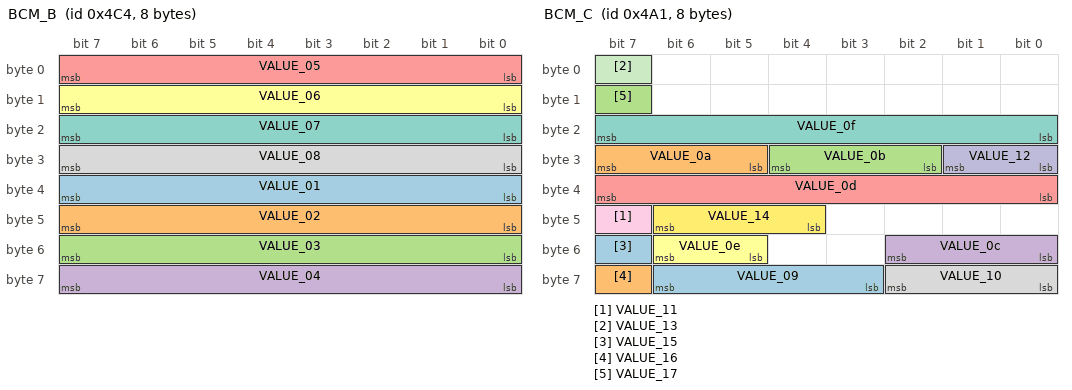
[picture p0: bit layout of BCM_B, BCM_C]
BO_ 1220 BCM_B: 8 BCM
 SG_ VALUE_01 : 39|8@0+ (1,0) [0|0] "" FCDIM
 SG_ VALUE_02 : 47|8@0+ (1,0) [0|0] "" FCDIM
 SG_ VALUE_03 : 55|8@0+ (1,0) [0|0] "" FCDIM
 SG_ VALUE_04 : 63|8@0+ (1,0) [0|0] "" FCDIM
 SG_ VALUE_05 : 7|8@0+ (1,0) [0|0] "" FCDIM
 SG_ VALUE_06 : 15|8@0+ (1,0) [0|0] "" FCDIM
 SG_ VALUE_07 : 23|8@0+ (1,0) [0|0] "" FCDIM
 SG_ VALUE_08 : 31|8@0+ (1,0) [0|0] "" FCDIM

BO_ 1185 BCM_C: 8 BCM
 SG_ VALUE_09 : 62|4@0+ (1,0) [0|15] "Colour Value" FCDIM
 SG_ VALUE_0a : 31|3@0+ (1,0) [6|7] "Unused (Undefined)" FCDIM
 SG_ VALUE_0b : 28|3@0+ (1,0) [6|7] "Unused (Undefined)" FCDIM
 SG_ VALUE_0c : 50|3@0+ (1,0) [6|7] "Unused (Undefined)" FCDIM
 SG_ VALUE_0d : 39|8@0+ (15,0) [3015|3810] "Reserved" FCDIM
 SG_ VALUE_0e : 54|2@0+ (1,0) [0|0] "" FCDIM
 SG_ VALUE_0f : 23|8@0+ (1,0) [13|255] "Invalid Range - Reserved" FCDIM
 SG_ VALUE_10 : 58|3@0+ (1,0) [6|7] "Unused (Undefined)" IPC
 SG_ VALUE_11 : 47|1@0+ (1,0) [0|0] "" FCDIM, FCIM, IPC, SODL, SODR
 SG_ VALUE_12 : 25|2@0+ (1,0) [0|0] "" FCDIM
 SG_ VALUE_13 : 7|1@0+ (1,0) [0|0] "" FCDIM, IPC
 SG_ VALUE_14 : 46|3@0+ (1,0) [0|0] "" FCDIM
 SG_ VALUE_15 : 55|1@0+ (1,0) [0|1] ""FCDIM
 SG_ VALUE_16 : 63|1@0+ (1,0) [0|0] "" FCDIM
 SG_ VALUE_17 : 15|1@0+ (1,0) [0|0] "" FCDIM

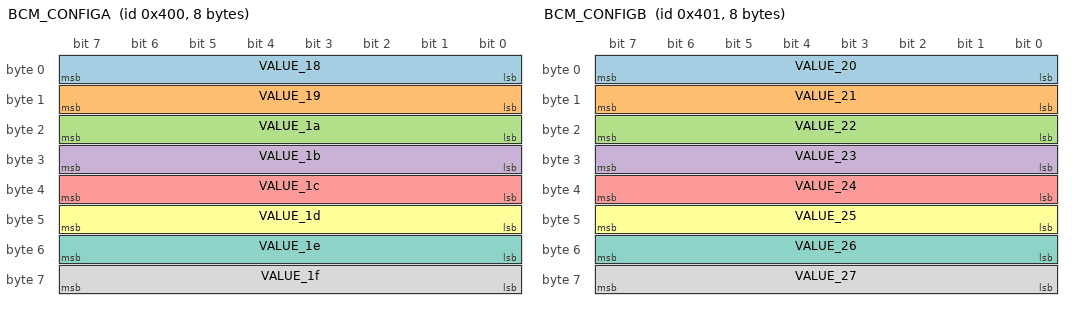
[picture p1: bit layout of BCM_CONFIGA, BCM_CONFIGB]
BO_ 1024 BCM_CONFIGA: 8 BCM
 SG_ VALUE_18 : 7|8@0+ (1,0) [0|0] "" CMR, DDM, FCDIM, FCIM, HCMB, HVAC, IPC, PCV, PDM, RFA, SODL, SODR
 SG_ VALUE_19 : 15|8@0+ (1,0) [0|0] "" CMR, DDM, FCDIM, FCIM, HCMB, HVAC, IPC, PCV, PDM, RFA, SODL, SODR
 SG_ VALUE_1a : 23|8@0+ (1,0) [0|0] "" CMR, DDM, FCDIM, FCIM, HCMB, HVAC, IPC, PCV, PDM, RFA, SODL, SODR
 SG_ VALUE_1b : 31|8@0+ (1,0) [0|0] "" CMR, DDM, FCDIM, FCIM, HCMB, HVAC, IPC, PCV, PDM, RFA, SODL, SODR
 SG_ VALUE_1c : 39|8@0+ (1,0) [0|0] "" CMR, DDM, FCDIM, FCIM, HCMB, HVAC, IPC, PCV, PDM, RFA, SODL, SODR
 SG_ VALUE_1d : 47|8@0+ (1,0) [0|0] "" CMR, DDM, FCDIM, FCIM, HCMB, HVAC, IPC, PCV, PDM, RFA, SODL, SODR
 SG_ VALUE_1e : 55|8@0+ (1,0) [0|0] "" CMR, DDM, FCDIM, FCIM, HCMB, HVAC, IPC, PCV, PDM, RFA, SODL, SODR
 SG_ VALUE_1f : 63|8@0+ (1,0) [0|0] "" CMR, DDM, FCDIM, FCIM, HCMB, HVAC, IPC, PCV, PDM, RFA, SODL, SODR

BO_ 1025 BCM_CONFIGB: 8 BCM
 SG_ VALUE_20 : 7|8@0+ (1,0) [0|0] "" DSM, FCDIM, FCIM, HCMB, IPC, PSM
 SG_ VALUE_21 : 15|8@0+ (1,0) [0|0] "" DSM, FCDIM, FCIM, HCMB, IPC, PSM
 SG_ VALUE_22 : 23|8@0+ (1,0) [0|0] "" DSM, FCDIM, FCIM, HCMB, IPC, PSM
 SG_ VALUE_23 : 31|8@0+ (1,0) [0|0] "" DSM, FCDIM, FCIM, HCMB, IPC, PSM
 SG_ VALUE_24 : 39|8@0+ (1,0) [0|0] "" DSM, FCDIM, FCIM, HCMB, IPC, PSM
 SG_ VALUE_25 : 47|8@0+ (1,0) [0|0] "" DSM, FCDIM, FCIM, HCMB, IPC, PSM
 SG_ VALUE_26 : 55|8@0+ (1,0) [0|0] "" DSM, FCDIM, FCIM, HCMB, IPC, PSM
 SG_ VALUE_27 : 63|8@0+ (1,0) [0|0] "" DSM, FCDIM, FCIM, HCMB, IPC, PSM
